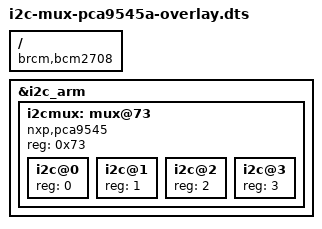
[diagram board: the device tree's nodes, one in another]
// Definitions for NXP PCA9545A I2C mux on ARM I2C bus.
/dts-v1/;
/plugin/;

/{
	compatible = "brcm,bcm2708";

	fragment@0 {
		target = <&i2c_arm>;
		__overlay__ {
			#address-cells = <1>;
			#size-cells = <0>;
			status = "okay";

			i2cmux: mux@73 {
				compatible = "nxp,pca9545";
				reg = <0x73>;
				#address-cells = <1>;
				#size-cells = <0>;

				i2c@0 {
					#address-cells = <1>;
					#size-cells = <0>;
					reg = <0>;
				};
				i2c@1 {
					#address-cells = <1>;
					#size-cells = <0>;
					reg = <1>;
				};
				i2c@2 {
					#address-cells = <1>;
					#size-cells = <0>;
					reg = <2>;
				};
				i2c@3 {
					#address-cells = <1>;
					#size-cells = <0>;
					reg = <3>;
				};
			};
		};
	};
	__overrides__ {
		addr = <&i2cmux>,"reg:0";
	};
};
